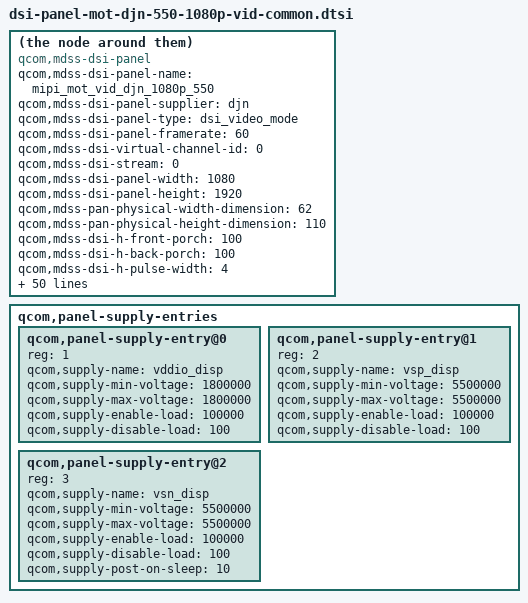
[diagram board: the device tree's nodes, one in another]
/* Copyright (c) 2016, The Linux Foundation. All rights reserved.
 *
 * This program is free software; you can redistribute it and/or modify
 * it under the terms of the GNU General Public License version 2 and
 * only version 2 as published by the Free Software Foundation.
 *
 * This program is distributed in the hope that it will be useful,
 * but WITHOUT ANY WARRANTY; without even the implied warranty of
 * MERCHANTABILITY or FITNESS FOR A PARTICULAR PURPOSE.  See the
 * GNU General Public License for more details.
 */

compatible = "qcom,mdss-dsi-panel";
qcom,mdss-dsi-panel-name = "mipi_mot_vid_djn_1080p_550";
qcom,mdss-dsi-panel-supplier = "djn";
qcom,mdss-dsi-panel-type = "dsi_video_mode";
qcom,mdss-dsi-panel-framerate = <60>;
qcom,mdss-dsi-virtual-channel-id = <0>;
qcom,mdss-dsi-stream = <0>;
qcom,mdss-dsi-panel-width = <1080>;
qcom,mdss-dsi-panel-height = <1920>;
qcom,mdss-pan-physical-width-dimension = <62>;
qcom,mdss-pan-physical-height-dimension = <110>;
qcom,mdss-dsi-h-front-porch = <100>;
qcom,mdss-dsi-h-back-porch = <100>;
qcom,mdss-dsi-h-pulse-width = <4>;
qcom,mdss-dsi-h-sync-skew = <0>;
qcom,mdss-dsi-v-back-porch = <16>;
qcom,mdss-dsi-v-front-porch = <16>;
qcom,mdss-dsi-v-pulse-width = <8>;
qcom,mdss-dsi-h-left-border = <0>;
qcom,mdss-dsi-h-right-border = <0>;
qcom,mdss-dsi-v-top-border = <0>;
qcom,mdss-dsi-v-bottom-border = <0>;
qcom,mdss-dsi-bpp = <24>;
qcom,mdss-dsi-underflow-color = <0xff>;
qcom,mdss-dsi-border-color = <0>;
qcom,mdss-dsi-on-command = [
	29 01 00 00 00 00 04 FF 78 07 05
	29 01 00 00 00 00 02 03 50
	29 01 00 00 00 00 02 04 02
	29 01 00 00 0A 00 04 FF 78 07 00
	29 01 00 00 00 00 03 51 0F FF
	29 01 00 00 00 00 02 53 2C
	29 01 00 00 00 00 02 55 01
	05 01 00 00 78 00 02 11 00
	05 01 00 00 0A 00 02 29 00
	29 01 00 00 0A 00 02 35 00];	/* display on */
qcom,mdss-dsi-off-command = [
	05 01 00 00 23 00 01 28		/* display_off */
	05 01 00 00 78 00 01 10];	/* enter sleep mode */


qcom,mdss-dsi-on-command-state = "dsi_lp_mode";
qcom,mdss-dsi-off-command-state = "dsi_lp_mode";

qcom,mdss-dsi-h-sync-pulse = <0>;
qcom,mdss-dsi-traffic-mode = "burst_mode";
qcom,mdss-dsi-bllp-eof-power-mode;
qcom,mdss-dsi-bllp-power-mode;
qcom,mdss-dsi-lane-0-state;
qcom,mdss-dsi-lane-1-state;
qcom,mdss-dsi-lane-2-state;
qcom,mdss-dsi-lane-3-state;
/* todo: calculate dsi timming with qcom doc again */
qcom,mdss-dsi-panel-timings-phy-v2 =
	[24 1F 08 09 05 03 04 A0
	24 1F 08 09 05 03 04 A0
	24 1F 08 09 05 03 04 A0
	24 1F 08 09 05 03 04 A0
	24 1B 08 09 05 03 04 A0];
qcom,mdss-dsi-panel-timings = [EB 38 26 00 6A 6C 2C 28 2F 03 04 00];
qcom,mdss-dsi-t-clk-post = <0x0D>;
qcom,mdss-dsi-t-clk-pre = <0x30>;
qcom,mdss-dsi-bl-min-level = <1>;
qcom,mdss-dsi-bl-max-level = <4095>;
qcom,mdss-dsi-dma-trigger = "trigger_sw";
qcom,mdss-dsi-mdp-trigger = "none";
qcom,mdss-dsi-bl-pmic-control-type = "bl_ctrl_wled";
qcom,mdss-dsi-reset-sequence = <1 10>, <0 10>, <1 120>;
qcom,mdss-dsi-lp11-init;
qcom,mdss-dsi-init-delay-us = <50000>;
qcom,mdss-dsi-tx-eot-append;

/* Enable ESD checking */
//qcom,esd-check-enabled;
qcom,mdss-dsi-panel-status-check-mode = "reg_read";
qcom,mdss-dsi-panel-status-read-length = <1>;
qcom,mdss-dsi-panel-status-command = [06 01 00 01 00 00 01 0A];
qcom,mdss-dsi-panel-status-command-state = "dsi_hs_mode";
qcom,mdss-dsi-panel-status-value = <0x9c>;

qcom,panel-supply-entries {
	#address-cells = <1>;
	#size-cells = <0>;

	qcom,panel-supply-entry@0 {
		reg = <1>;
		qcom,supply-name = "vddio_disp";
		qcom,supply-min-voltage = <1800000>;
		qcom,supply-max-voltage = <1800000>;
		qcom,supply-enable-load = <100000>;
		qcom,supply-disable-load = <100>;
	};

	qcom,panel-supply-entry@1 {
		reg = <2>;
		qcom,supply-name = "vsp_disp";
		qcom,supply-min-voltage = <5500000>;
		qcom,supply-max-voltage = <5500000>;
		qcom,supply-enable-load = <100000>;
		qcom,supply-disable-load = <100>;
	};

	qcom,panel-supply-entry@2 {
		reg = <3>;
		qcom,supply-name = "vsn_disp";
		qcom,supply-min-voltage = <5500000>;
		qcom,supply-max-voltage = <5500000>;
		qcom,supply-enable-load = <100000>;
		qcom,supply-disable-load = <100>;
		qcom,supply-post-on-sleep = <10>;
	};
};
